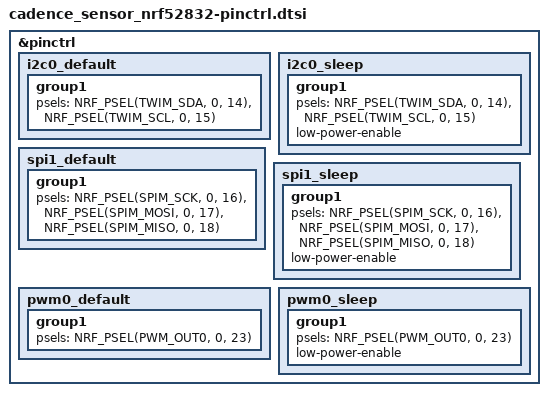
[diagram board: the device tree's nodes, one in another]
/* SPDX-License-Identifier: Apache-2.0 */

#include <zephyr/dt-bindings/pinctrl/nrf-pinctrl.h>

&pinctrl {
	i2c0_default: i2c0_default {
		group1 {
			psels = <NRF_PSEL(TWIM_SDA, 0, 14)>,
				<NRF_PSEL(TWIM_SCL, 0, 15)>;
		};
	};

	i2c0_sleep: i2c0_sleep {
		group1 {
			psels = <NRF_PSEL(TWIM_SDA, 0, 14)>,
				<NRF_PSEL(TWIM_SCL, 0, 15)>;
			low-power-enable;
		};
	};

	spi1_default: spi1_default {
		group1 {
			psels = <NRF_PSEL(SPIM_SCK, 0, 16)>,
				<NRF_PSEL(SPIM_MOSI, 0, 17)>,
				<NRF_PSEL(SPIM_MISO, 0, 18)>;
		};
	};

	spi1_sleep: spi1_sleep {
		group1 {
			psels = <NRF_PSEL(SPIM_SCK, 0, 16)>,
				<NRF_PSEL(SPIM_MOSI, 0, 17)>,
				<NRF_PSEL(SPIM_MISO, 0, 18)>;
			low-power-enable;
		};
	};

	pwm0_default: pwm0_default {
		group1 {
			psels = <NRF_PSEL(PWM_OUT0, 0, 23)>;
		};
	};

	pwm0_sleep: pwm0_sleep {
		group1 {
			psels = <NRF_PSEL(PWM_OUT0, 0, 23)>;
			low-power-enable;
		};
	};
};
